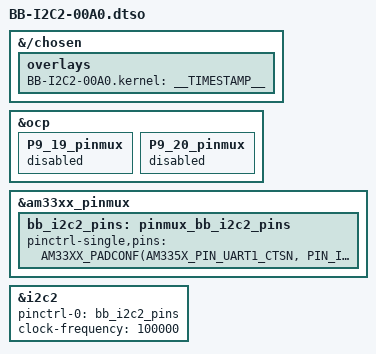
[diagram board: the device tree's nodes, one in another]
// SPDX-License-Identifier: GPL-2.0-only
/*
 * Copyright (C) 2013 CircuitCo
 *
 * Virtual cape for I2C2 on connector pins P9.19 P9.20
 */

/dts-v1/;
/plugin/;

#include <dt-bindings/pinctrl/am33xx.h>

/*
 * Helper to show loaded overlays under: /proc/device-tree/chosen/overlays/
 */
&{/chosen} {
	overlays {
		BB-I2C2-00A0.kernel = __TIMESTAMP__;
	};
};

/*
 * Free up the pins used by the cape from the pinmux helpers.
 */
&ocp {
	P9_19_pinmux { status = "disabled"; };	/* i2c2_scl */
	P9_20_pinmux { status = "disabled"; };	/* i2c2_sda */
};

&am33xx_pinmux {
	bb_i2c2_pins: pinmux_bb_i2c2_pins {
		pinctrl-single,pins = <
			AM33XX_PADCONF(AM335X_PIN_UART1_CTSN, PIN_INPUT_PULLUP, MUX_MODE3)	/* uart1_ctsn.i2c2_sda */
			AM33XX_PADCONF(AM335X_PIN_UART1_RTSN, PIN_INPUT_PULLUP, MUX_MODE3)	/* uart1_rtsn.i2c2_scl */
		>;
	};
};

&i2c2 {
	status = "okay";
	pinctrl-names = "default";
	pinctrl-0 = <&bb_i2c2_pins>;

	clock-frequency = <100000>;
};
